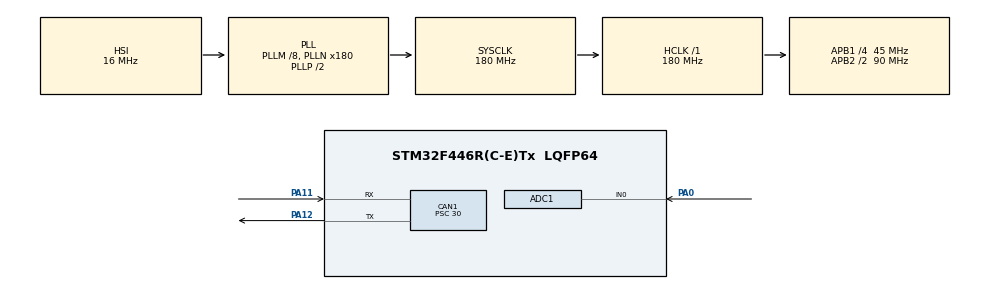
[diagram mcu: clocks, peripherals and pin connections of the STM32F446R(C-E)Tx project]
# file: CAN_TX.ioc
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ADC1.Channel-0\#ChannelRegularConversion=ADC_CHANNEL_0
ADC1.ContinuousConvMode=ENABLE
ADC1.NbrOfConversionFlag=1
ADC1.Rank-0\#ChannelRegularConversion=1
ADC1.SamplingTime-0\#ChannelRegularConversion=ADC_SAMPLETIME_3CYCLES
ADC1.master=1
CAN1.CalculateBaudRate=500000
CAN1.CalculateTimeBit=2000
CAN1.CalculateTimeQuantum=666.6666666666666
CAN1.Prescaler=30
Mcu.Family=STM32F4
Mcu.Name=STM32F446R(C-E)Tx
Mcu.Package=LQFP64
NVIC.PriorityGroup=NVIC_PRIORITYGROUP_4
PA0-WKUP.Signal=ADCx_IN0
PA11.Mode=CAN_Activate
PA11.Signal=CAN1_RX
PA12.Mode=CAN_Activate
PA12.Signal=CAN1_TX
PA13.Mode=Serial_Wire
PA13.Signal=SYS_JTMS-SWDIO
PA14.Mode=Serial_Wire
PA14.Signal=SYS_JTCK-SWCLK
ProjectManager.HeapSize=0x200
ProjectManager.StackSize=0x400
ProjectManager.TargetToolchain=STM32CubeIDE
RCC.AHBFreq_Value=180000000
RCC.APB1CLKDivider=RCC_HCLK_DIV4
RCC.APB1Freq_Value=45000000
RCC.APB1TimFreq_Value=90000000
RCC.APB2CLKDivider=RCC_HCLK_DIV2
RCC.APB2Freq_Value=90000000
RCC.APB2TimFreq_Value=180000000
RCC.CortexFreq_Value=180000000
RCC.HCLKFreq_Value=180000000
RCC.PLLM=8
RCC.PLLN=180
RCC.SYSCLKFreq_VALUE=180000000
RCC.SYSCLKSource=RCC_SYSCLKSOURCE_PLLCLK
RCC.USBFreq_Value=180000000
RCC.VCOOutputFreq_Value=360000000
SH.ADCx_IN0.0=ADC1_IN0,IN0
board=custom

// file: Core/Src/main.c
/* USER CODE BEGIN Header */
/**
 ******************************************************************************
 * @file           : main.c
 * @brief          : Main program body
 ******************************************************************************
 * @attention
 *
 * Copyright (c) 2025 STMicroelectronics.
 * All rights reserved.
 *
 * This software is licensed under terms that can be found in the LICENSE file
 * in the root directory of this software component.
 * If no LICENSE file comes with this software, it is provided AS-IS.
 *
 ******************************************************************************
 */
/* USER CODE END Header */
#include "main.h"

/* USER CODE BEGIN Includes */

#include <stdio.h>

/* USER CODE END Includes */

ADC_HandleTypeDef hadc1;

CAN_HandleTypeDef hcan1;

void SystemClock_Config(void);
static void MX_GPIO_Init(void);
static void MX_ADC1_Init(void);
static void MX_CAN1_Init(void);

/* USER CODE BEGIN 0 */

// uint16_t readValue;
// CAN_TxHeaderTypeDef TxHeader;
// uint32_t TxMailbox;
// uint8_t TxData[3] = "._.";
int _write(int file, char *ptr, int len) {
	(void) file;
	int DataIdx;

	for (DataIdx = 0; DataIdx < len; DataIdx++) {
		ITM_SendChar(*ptr++);
	}
	return len;
}

/* USER CODE END 0 */

int main(void) {

	/* MCU Configuration--------------------------------------------------------*/

	/* Reset of all peripherals, Initializes the Flash interface and the Systick. */
	HAL_Init();

	/* Configure the system clock */
	SystemClock_Config();

	/* Initialize all configured peripherals */
	MX_GPIO_Init();
	MX_ADC1_Init();
	MX_CAN1_Init();
	/* USER CODE BEGIN 2 */

	// HAL_ADC_Start(&hadc1);
	// HAL_CAN_Start(&hcan1);
	// TxHeader.DLC = 3;  				// data length
	// TxHeader.IDE = CAN_ID_STD;
	// TxHeader.RTR = CAN_RTR_DATA;
	// TxHeader.StdId = 0x12;  		// ID can be between Hex1 and Hex7FF (1-2047 decimal)
	CAN_FilterTypeDef filter;
	filter.FilterIdHigh = 0x0000;
	filter.FilterIdLow = 0x0000;
	filter.FilterMaskIdHigh = 0x0000;
	filter.FilterMaskIdLow = 0x0000;
	HAL_CAN_ConfigFilter(&hcan1, &filter);
	HAL_CAN_Start(&hcan1);

	CAN_RxHeaderTypeDef rxHeader;
	uint8_t rxData[8];

	/* USER CODE END 2 */

	/* Infinite loop */
	/* USER CODE BEGIN WHILE */

	while (1) {
		// HAL_ADC_PollForConversion(&hadc1, 1000);
		// readValue = HAL_ADC_GetValue(&hadc1);

		// readValue is between 0-4095 but we need to transmit maximum 255 (one byte)
		// We divide readValue by 16 to get 0-255. Better way to divide is by shifting bits
		// (readValue >> 4) is same as (readValue / 16)
		// TxData[7] = readValue >> 4;

		// TxData[0] = '.';
		// TxData[1] = '_';
		// TxData[2] = '.';
		// if (HAL_CAN_AddTxMessage(&hcan1, &TxHeader, TxData, &TxMailbox) == HAL_OK) {
		// printf("Sent...\n");
		// }
		// HAL_Delay(500);

		//if (HAL_CAN_GetRxFifoFillLevel(&hcan1, CAN_RX_FIFO0) > 0) {
			if (HAL_CAN_GetRxMessage(&hcan1, CAN_RX_FIFO0, &rxHeader, rxData) == HAL_OK) {
				// if (rxHeader.StdId == 0x12) {
					printf("Received from 0x12: %c %c\n", rxData[0], rxData[1]);
				// }
			}
		//}
		HAL_Delay(500);

		/* USER CODE END WHILE */

	}
}

void SystemClock_Config(void) {
	RCC_OscInitTypeDef RCC_OscInitStruct = { 0 };
	RCC_ClkInitTypeDef RCC_ClkInitStruct = { 0 };

	/** Configure the main internal regulator output voltage
	 */
	__HAL_RCC_PWR_CLK_ENABLE();
	__HAL_PWR_VOLTAGESCALING_CONFIG(PWR_REGULATOR_VOLTAGE_SCALE1);

	/** Initializes the RCC Oscillators according to the specified parameters
	 * in the RCC_OscInitTypeDef structure.
	 */
	RCC_OscInitStruct.OscillatorType = RCC_OSCILLATORTYPE_HSI;
	RCC_OscInitStruct.HSIState = RCC_HSI_ON;
	RCC_OscInitStruct.HSICalibrationValue = RCC_HSICALIBRATION_DEFAULT;
	RCC_OscInitStruct.PLL.PLLState = RCC_PLL_ON;
	RCC_OscInitStruct.PLL.PLLSource = RCC_PLLSOURCE_HSI;
	RCC_OscInitStruct.PLL.PLLM = 8;
	RCC_OscInitStruct.PLL.PLLN = 180;
	RCC_OscInitStruct.PLL.PLLP = RCC_PLLP_DIV2;
	RCC_OscInitStruct.PLL.PLLQ = 2;
	RCC_OscInitStruct.PLL.PLLR = 2;
	if (HAL_RCC_OscConfig(&RCC_OscInitStruct) != HAL_OK) {
		Error_Handler();
	}

	/** Activate the Over-Drive mode
	 */
	if (HAL_PWREx_EnableOverDrive() != HAL_OK) {
		Error_Handler();
	}

	/** Initializes the CPU, AHB and APB buses clocks
	 */
	RCC_ClkInitStruct.ClockType = RCC_CLOCKTYPE_HCLK | RCC_CLOCKTYPE_SYSCLK | RCC_CLOCKTYPE_PCLK1 | RCC_CLOCKTYPE_PCLK2;
	RCC_ClkInitStruct.SYSCLKSource = RCC_SYSCLKSOURCE_PLLCLK;
	RCC_ClkInitStruct.AHBCLKDivider = RCC_SYSCLK_DIV1;
	RCC_ClkInitStruct.APB1CLKDivider = RCC_HCLK_DIV4;
	RCC_ClkInitStruct.APB2CLKDivider = RCC_HCLK_DIV2;

	if (HAL_RCC_ClockConfig(&RCC_ClkInitStruct, FLASH_LATENCY_5) != HAL_OK) {
		Error_Handler();
	}
}

static void MX_ADC1_Init(void) {

	ADC_ChannelConfTypeDef sConfig = { 0 };

	/** Configure the global features of the ADC (Clock, Resolution, Data Alignment and number of conversion)
	 */
	hadc1.Instance = ADC1;
	hadc1.Init.ClockPrescaler = ADC_CLOCK_SYNC_PCLK_DIV4;
	hadc1.Init.Resolution = ADC_RESOLUTION_12B;
	hadc1.Init.ScanConvMode = DISABLE;
	hadc1.Init.ContinuousConvMode = ENABLE;
	hadc1.Init.DiscontinuousConvMode = DISABLE;
	hadc1.Init.ExternalTrigConvEdge = ADC_EXTERNALTRIGCONVEDGE_NONE;
	hadc1.Init.ExternalTrigConv = ADC_SOFTWARE_START;
	hadc1.Init.DataAlign = ADC_DATAALIGN_RIGHT;
	hadc1.Init.NbrOfConversion = 1;
	hadc1.Init.DMAContinuousRequests = DISABLE;
	hadc1.Init.EOCSelection = ADC_EOC_SINGLE_CONV;
	if (HAL_ADC_Init(&hadc1) != HAL_OK) {
		Error_Handler();
	}

	/** Configure for the selected ADC regular channel its corresponding rank in the sequencer and its sample time.
	 */
	sConfig.Channel = ADC_CHANNEL_0;
	sConfig.Rank = 1;
	sConfig.SamplingTime = ADC_SAMPLETIME_3CYCLES;
	if (HAL_ADC_ConfigChannel(&hadc1, &sConfig) != HAL_OK) {
		Error_Handler();
	}

}

static void MX_CAN1_Init(void) {

	hcan1.Instance = CAN1;
	hcan1.Init.Prescaler = 30;
	hcan1.Init.Mode = CAN_MODE_NORMAL;
	hcan1.Init.SyncJumpWidth = CAN_SJW_1TQ;
	hcan1.Init.TimeSeg1 = CAN_BS1_1TQ;
	hcan1.Init.TimeSeg2 = CAN_BS2_1TQ;
	hcan1.Init.TimeTriggeredMode = DISABLE;
	hcan1.Init.AutoBusOff = DISABLE;
	hcan1.Init.AutoWakeUp = DISABLE;
	hcan1.Init.AutoRetransmission = DISABLE;
	hcan1.Init.ReceiveFifoLocked = DISABLE;
	hcan1.Init.TransmitFifoPriority = DISABLE;
	if (HAL_CAN_Init(&hcan1) != HAL_OK) {
		Error_Handler();
	}

}

static void MX_GPIO_Init(void) {

	/* GPIO Ports Clock Enable */
	__HAL_RCC_GPIOA_CLK_ENABLE();

}

void Error_Handler(void) {
	__disable_irq();
	while (1) {
	}
}
